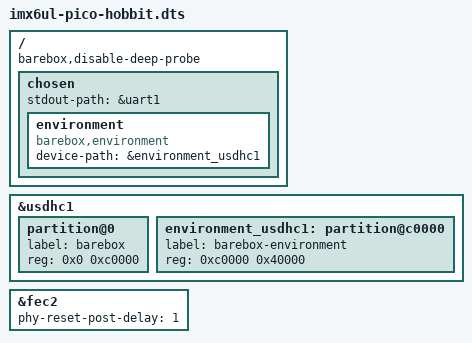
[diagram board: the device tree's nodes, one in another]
#include <arm/nxp/imx/imx6ul-pico-hobbit.dts>

/ {
	barebox,disable-deep-probe;

	chosen {
		stdout-path = &uart1;

		environment {
			compatible = "barebox,environment";
			device-path = &environment_usdhc1;
		};
	};
};

&usdhc1 {
	#address-cells = <1>;
	#size-cells = <1>;

	partition@0 {
		label = "barebox";
		reg = <0x0 0xc0000>;
	};

	environment_usdhc1: partition@c0000 {
		label = "barebox-environment";
		reg = <0xc0000 0x40000>;
	};
};

&fec2 {
	phy-reset-post-delay = <1>;
};
